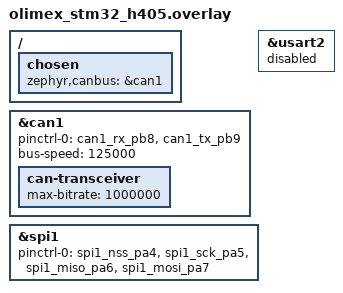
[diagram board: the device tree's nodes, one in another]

/ {
	chosen {
		zephyr,canbus = &can1;
	};
};

&can1 {
	pinctrl-0 = <&can1_rx_pb8 &can1_tx_pb9>;
	pinctrl-names = "default";
	bus-speed = <125000>;
	status = "okay";
	can-transceiver {
		max-bitrate = <1000000>;
	};
};

&usart2 {
	status = "disabled";
};

&spi1 {
	pinctrl-0 = <&spi1_nss_pa4 &spi1_sck_pa5
		     &spi1_miso_pa6 &spi1_mosi_pa7>;
	pinctrl-names = "default";
	status = "okay";
};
